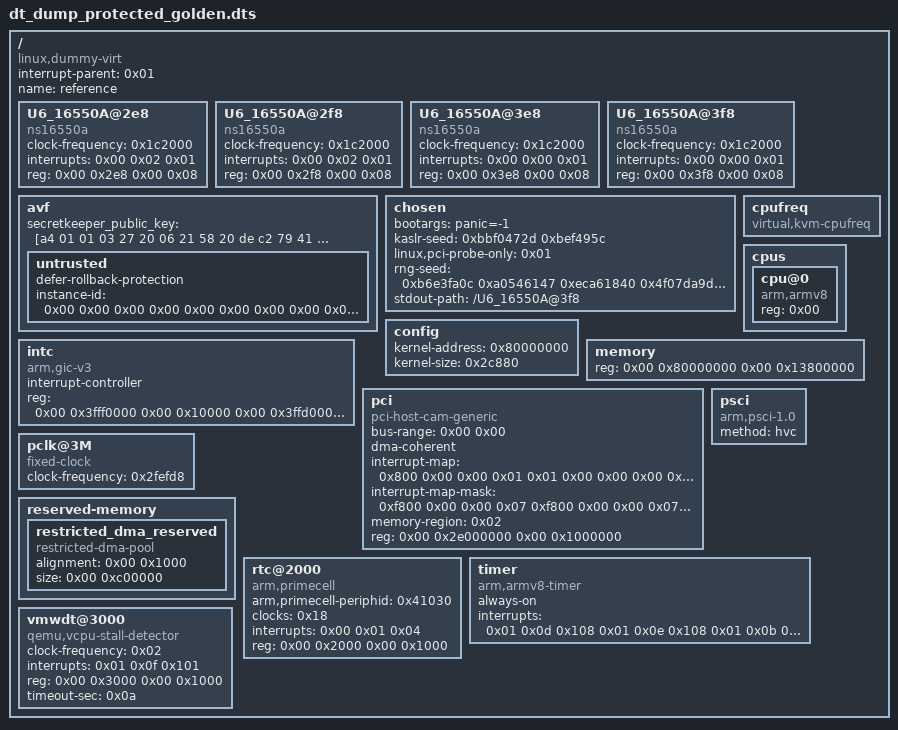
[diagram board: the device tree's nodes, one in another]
/dts-v1/;

/ {
	#address-cells = <0x02>;
	#size-cells = <0x02>;
	compatible = "linux,dummy-virt";
	interrupt-parent = <0x01>;
	name = "reference";

	U6_16550A@2e8 {
		clock-frequency = <0x1c2000>;
		compatible = "ns16550a";
		interrupts = <0x00 0x02 0x01>;
		reg = <0x00 0x2e8 0x00 0x08>;
	};

	U6_16550A@2f8 {
		clock-frequency = <0x1c2000>;
		compatible = "ns16550a";
		interrupts = <0x00 0x02 0x01>;
		reg = <0x00 0x2f8 0x00 0x08>;
	};

	U6_16550A@3e8 {
		clock-frequency = <0x1c2000>;
		compatible = "ns16550a";
		interrupts = <0x00 0x00 0x01>;
		reg = <0x00 0x3e8 0x00 0x08>;
	};

	U6_16550A@3f8 {
		clock-frequency = <0x1c2000>;
		compatible = "ns16550a";
		interrupts = <0x00 0x00 0x01>;
		reg = <0x00 0x3f8 0x00 0x08>;
	};

	__symbols__ {
		intc = "/intc";
	};

	avf {
		secretkeeper_public_key = [a4 01 01 03 27 20 06 21 58 20 de c2 79 41 b5 2a d8 1e eb dd 8a c5 a0 2f e4 56 12 42 5e b5 a4 c6 6a 8c 32 81 65 75 1c 6e b2 87];

		untrusted {
			defer-rollback-protection;
			instance-id = <0x00 0x00 0x00 0x00 0x00 0x00 0x00 0x00 0x00 0x00 0x00 0x00 0x00 0x00 0x00 0x00>;
		};
	};

	chosen {
		bootargs = "panic=-1";
		kaslr-seed = <0xbbf0472d 0xbef495c>;
		linux,pci-probe-only = <0x01>;
		rng-seed = <0xb6e3fa0c 0xa0546147 0xeca61840 0x4f07da9d 0xacb41a21 0x8aa7ff1f 0xd32dd43 0x93fb4ad3 0xab5f9bf1 0x66d5913d 0x2b389a9f 0xc2c268d2 0xfd1d9a22 0xa8dba850 0xd443014d 0x10b3dfcb 0x77597882 0x66008b71 0x3d29575c 0xd917ee2f 0xb6e98504 0x6a5c9fde 0xa02daf16 0x3a60b1d5 0xa4416447 0x9e8a996d 0x3b4bf5e9 0xdf7639cb 0x4b608f7e 0x3434d9b4 0xb84cd15 0x86d724ae 0x404a1353 0x8afc6a43 0x916c4b8d 0xebe878c0 0xd67a99a4 0x94fb22ca 0xef53a3bf 0xaf5fc4b 0xd6d405d8 0xb6ed6cb5 0xc4d13a21 0x6aff3f79 0x93b56581 0x622e8da3 0x59047c4b 0x9a7562ee 0x93762d9a 0xeab995f7 0x33e1cdea 0x5d071401 0x2d57f0d1 0x73367772 0x532a74b6 0x3fb875fe 0x7340d4dd 0x492fa79f 0x7749f27 0xe8eefd10 0xeb00c401 0xd51bd6b3 0x904b5ac8 0x4316f75b>;
		stdout-path = "/U6_16550A@3f8";
	};

	config {
		kernel-address = <0x80000000>;
		kernel-size = <0x2c880>;
	};

	cpufreq {
		compatible = "virtual,kvm-cpufreq";
	};

	cpus {
		#address-cells = <0x01>;
		#size-cells = <0x00>;

		cpu@0 {
			compatible = "arm,armv8";
			device_type = "cpu";
			phandle = <0x100>;
			reg = <0x00>;
		};
	};

	intc {
		#address-cells = <0x02>;
		#interrupt-cells = <0x03>;
		#size-cells = <0x02>;
		compatible = "arm,gic-v3";
		interrupt-controller;
		phandle = <0x01>;
		reg = <0x00 0x3fff0000 0x00 0x10000 0x00 0x3ffd0000 0x00 0x20000>;
	};

	memory {
		device_type = "memory";
		reg = <0x00 0x80000000 0x00 0x13800000>;
	};

	pci {
		#address-cells = <0x03>;
		#interrupt-cells = <0x01>;
		#size-cells = <0x02>;
		bus-range = <0x00 0x00>;
		compatible = "pci-host-cam-generic";
		device_type = "pci";
		dma-coherent;
		interrupt-map = <0x800 0x00 0x00 0x01 0x01 0x00 0x00 0x00 0x04 0x04 0x1000 0x00 0x00 0x01 0x01 0x00 0x00 0x00 0x05 0x04 0x1800 0x00 0x00 0x01 0x01 0x00 0x00 0x00 0x06 0x04 0x2000 0x00 0x00 0x01 0x01 0x00 0x00 0x00 0x07 0x04 0x2800 0x00 0x00 0x01 0x01 0x00 0x00 0x00 0x08 0x04 0x3000 0x00 0x00 0x01 0x01 0x00 0x00 0x00 0x09 0x04 0x3800 0x00 0x00 0x01 0x01 0x00 0x00 0x00 0x0a 0x04>;
		interrupt-map-mask = <0xf800 0x00 0x00 0x07 0xf800 0x00 0x00 0x07 0xf800 0x00 0x00 0x07 0xf800 0x00 0x00 0x07 0xf800 0x00 0x00 0x07 0xf800 0x00 0x00 0x07 0xf800 0x00 0x00 0x07>;
		memory-region = <0x02>;
		ranges = <0x3000000 0x00 0x2c000000 0x00 0x2c000000 0x00 0x2000000 0x43000000 0x00 0x94000000 0x00 0x94000000 0xff 0x6c000000>;
		reg = <0x00 0x2e000000 0x00 0x1000000>;
	};

	pclk@3M {
		#clock-cells = <0x00>;
		clock-frequency = <0x2fefd8>;
		compatible = "fixed-clock";
		phandle = <0x18>;
	};

	psci {
		compatible = "arm,psci-1.0\0arm,psci-0.2";
		method = "hvc";
	};

	reserved-memory {
		#address-cells = <0x02>;
		#size-cells = <0x02>;
		ranges;

		restricted_dma_reserved {
			alignment = <0x00 0x1000>;
			compatible = "restricted-dma-pool";
			phandle = <0x02>;
			size = <0x00 0xc00000>;
		};
	};

	rtc@2000 {
		arm,primecell-periphid = <0x41030>;
		clock-names = "apb_pclk";
		clocks = <0x18>;
		compatible = "arm,primecell";
		interrupts = <0x00 0x01 0x04>;
		reg = <0x00 0x2000 0x00 0x1000>;
	};

	timer {
		always-on;
		compatible = "arm,armv8-timer";
		interrupts = <0x01 0x0d 0x108 0x01 0x0e 0x108 0x01 0x0b 0x108 0x01 0x0a 0x108>;
	};

	vmwdt@3000 {
		clock-frequency = <0x02>;
		compatible = "qemu,vcpu-stall-detector";
		interrupts = <0x01 0x0f 0x101>;
		reg = <0x00 0x3000 0x00 0x1000>;
		timeout-sec = <0x0a>;
	};
};
